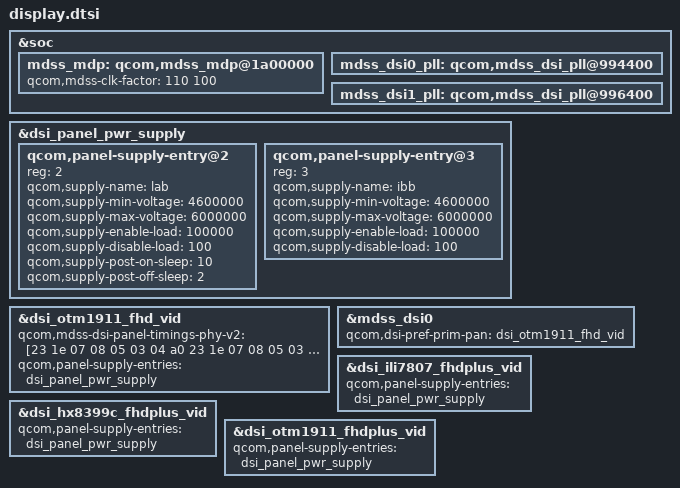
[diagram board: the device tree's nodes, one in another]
#include "../common/panel/dsi-panel-otm1911-fhd-video.dtsi"
#include "../common/panel/dsi-panel-otm1911-fhdplus-video.dtsi"
#include "../common/panel/dsi-panel-ili7807-fhdplus-video.dtsi"
#include "../common/panel/dsi-panel-hx8399c-fhdplus-video.dtsi"

/* msm8953-mdss */
&soc {
	mdss_mdp: qcom,mdss_mdp@1a00000 {
			qcom,mdss-clk-factor = <110 100>;	/* 1.10 times */
	};
};

/* msm8953-mdss-pll */
&soc {
	mdss_dsi0_pll: qcom,mdss_dsi_pll@994400 {
		/delete-property/ qcom,dsi-pll-ssc-en;
		/delete-property/ qcom,dsi-pll-ssc-mode;
	};
	mdss_dsi1_pll: qcom,mdss_dsi_pll@996400 {
		/delete-property/ qcom,dsi-pll-ssc-en;
		/delete-property/ qcom,dsi-pll-ssc-mode;
	};
};

&dsi_panel_pwr_supply {
	qcom,panel-supply-entry@2 {
		reg = <2>;
		qcom,supply-name = "lab";
		qcom,supply-min-voltage = <4600000>;
		qcom,supply-max-voltage = <6000000>;
		qcom,supply-enable-load = <100000>;
		qcom,supply-disable-load = <100>;
		qcom,supply-post-on-sleep = <10>;
		qcom,supply-post-off-sleep = <2>;
	};

	qcom,panel-supply-entry@3 {
		reg = <3>;
		qcom,supply-name = "ibb";
		qcom,supply-min-voltage = <4600000>;
		qcom,supply-max-voltage = <6000000>;
		qcom,supply-enable-load = <100000>;
		qcom,supply-disable-load = <100>;
		/*qcom,supply-post-on-sleep = <10>;*/
	};
};

&dsi_otm1911_fhd_vid {
	qcom,mdss-dsi-panel-timings-phy-v2 = [23 1e 07 08 05 03 04 a0
		23 1e 07 08 05 03 04 a0
		23 1e 07 08 05 03 04 a0
		23 1e 07 08 05 03 04 a0
		23 18 07 08 05 03 04 a0];
};

&mdss_dsi0 {
	qcom,dsi-pref-prim-pan = <&dsi_otm1911_fhd_vid>;
};

&dsi_otm1911_fhd_vid {
	qcom,panel-supply-entries = <&dsi_panel_pwr_supply>;
};

&dsi_ili7807_fhdplus_vid {
	qcom,panel-supply-entries = <&dsi_panel_pwr_supply>;
};

&dsi_hx8399c_fhdplus_vid {
	qcom,panel-supply-entries = <&dsi_panel_pwr_supply>;
};

&dsi_otm1911_fhdplus_vid {
	qcom,panel-supply-entries = <&dsi_panel_pwr_supply>;

};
